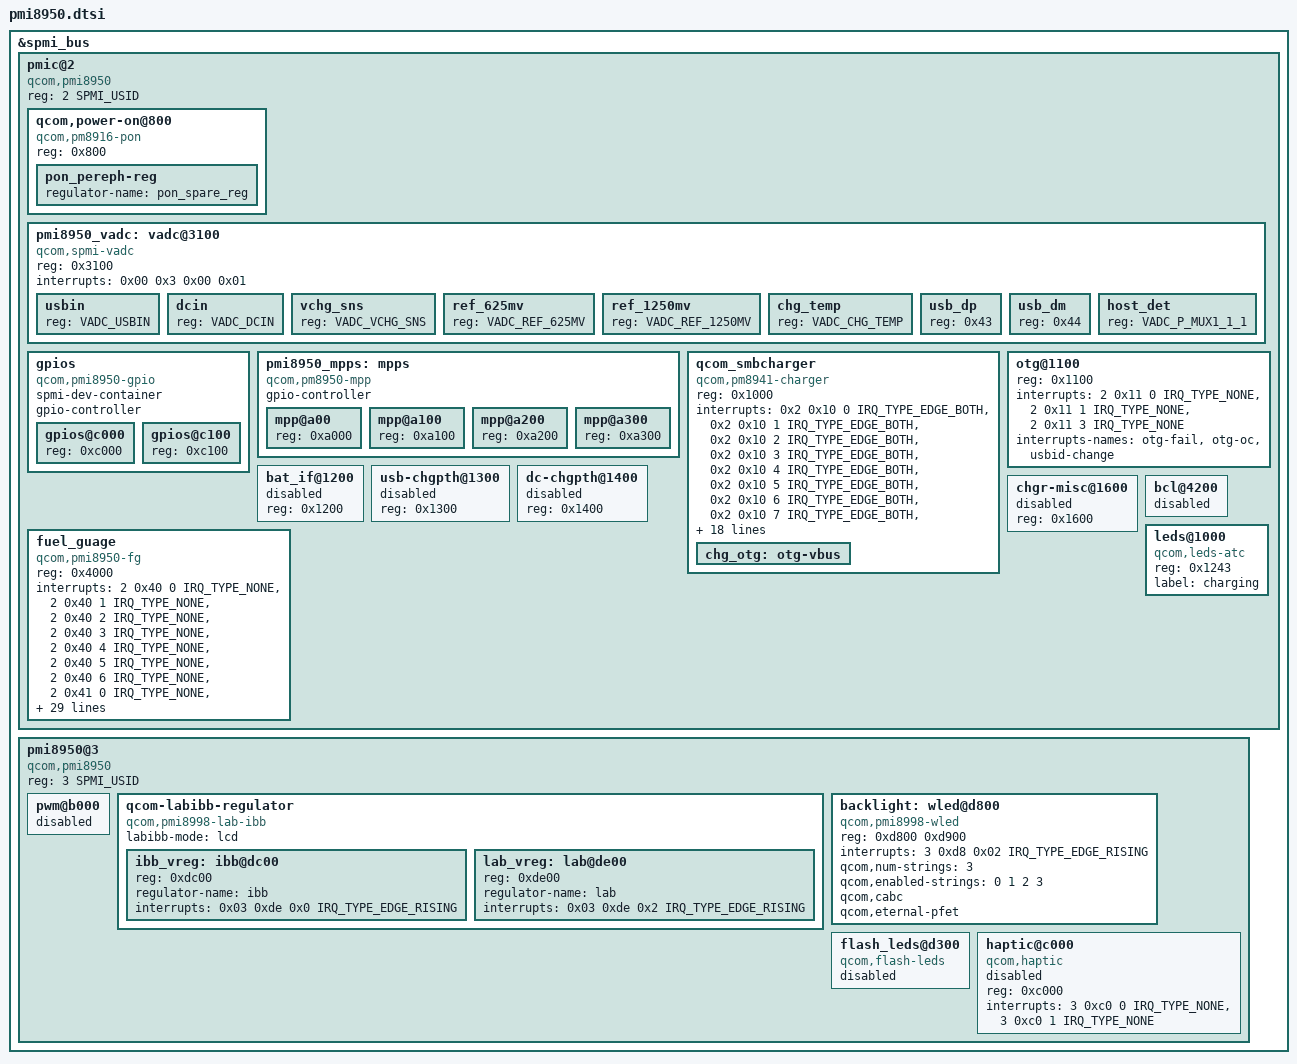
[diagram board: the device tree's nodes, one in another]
// SPDX-License-Identifier: GPL-2.0-only
/* Copyright (c) 2020, The Linux Foundation. All rights reserved.
 */
#include <dt-bindings/iio/qcom,spmi-vadc.h>
#include <dt-bindings/interrupt-controller/irq.h>
#include <dt-bindings/input/linux-event-codes.h>
#include <dt-bindings/spmi/spmi.h>

&spmi_bus {
	pmic@2 {
		compatible = "qcom,pmi8950", "qcom,spmi-pmic";
		reg = <2 SPMI_USID>;
		#address-cells = <1>;
		#size-cells = <0>;

		qcom,power-on@800 {
			compatible = "qcom,pm8916-pon"; //FIXME is this the correct driver
			reg = <0x800>;			//This pmic may be gen2 unlike 8916
			//qcom,secondary-pon-reset;
			//qcom,hard-reset-poweroff-type = <0x04>;
			pon_pereph-reg {
				//TODO:
				regulator-name = "pon_spare_reg";
			};
		};

		pmi8950_vadc: vadc@3100 {
			compatible = "qcom,spmi-vadc";
			reg = <0x3100>;
			interrupts = <0x00 0x3 0x00 0x01>;
			#address-cells = <1>;
			#size-cells = <0>;
			#io-channel-cells = <1>;

			usbin {
				reg = <VADC_USBIN>;
			};

			dcin {
				reg = <VADC_DCIN>;
			};

			vchg_sns {
				reg = <VADC_VCHG_SNS>;
			};

			ref_625mv {
				reg = <VADC_REF_625MV>;
			};

			ref_1250mv {
				reg = <VADC_REF_1250MV>;
			};

			chg_temp {
				reg = <VADC_CHG_TEMP>;
			};

			usb_dp {
				//FIXME: Unsupported?
				reg = <0x43>;
			};

			usb_dm {
				//FIXME: Unsupported?
				reg = <0x44>;
			};

			host_det {
				//FIXME: Unsupported?
				reg = <VADC_P_MUX1_1_1>;
			};
		};

		gpios {
			spmi-dev-container;
			compatible = "qcom,pmi8950-gpio";
			gpio-controller;
			#gpio-cells = <2>;
			#address-cells = <1>;
			#size-cells = <0>;

			gpios@c000 {
				reg = <0xc000>;
				status = "okay";
			};

			gpios@c100 {
				reg = <0xc100>;
				status = "okay";
			};
		};

		pmi8950_mpps: mpps {
			compatible = "qcom,pm8950-mpp";
			gpio-controller;
			#gpio-cells = <2>;
			#address-cells = <1>;
			#size-cells = <0>;

			mpp@a00 {
				reg = <0xa000>;
				status = "okay";
			};

			mpp@a100 {
				reg = <0xa100>;
				status = "okay";
			};

			mpp@a200 {
				reg = <0xa200>;
				status = "okay";
			};

			mpp@a300 {
				reg = <0xa300>;
				status = "okay";
			};
		};

		qcom_smbcharger {
			compatible = "qcom,pm8941-charger";
			reg = <0x1000>;
			status = "okay";

			interrupts = <0x2 0x10 0 IRQ_TYPE_EDGE_BOTH>,
				     <0x2 0x10 1 IRQ_TYPE_EDGE_BOTH>,
				     <0x2 0x10 2 IRQ_TYPE_EDGE_BOTH>,
				     <0x2 0x10 3 IRQ_TYPE_EDGE_BOTH>,
				     <0x2 0x10 4 IRQ_TYPE_EDGE_BOTH>,
				     <0x2 0x10 5 IRQ_TYPE_EDGE_BOTH>,
				     <0x2 0x10 6 IRQ_TYPE_EDGE_BOTH>,
				     <0x2 0x10 7 IRQ_TYPE_EDGE_BOTH>,
				     <0x2 0x12 0 IRQ_TYPE_EDGE_BOTH>,
				     <0x2 0x12 1 IRQ_TYPE_EDGE_BOTH>,
				     <0x2 0x12 2 IRQ_TYPE_EDGE_BOTH>,
				     <0x2 0x12 3 IRQ_TYPE_EDGE_BOTH>,
				     <0x2 0x12 4 IRQ_TYPE_EDGE_BOTH>,
				     <0x2 0x12 5 IRQ_TYPE_EDGE_BOTH>,
				     <0x2 0x12 6 IRQ_TYPE_EDGE_BOTH>,
				     <0x2 0x12 7 IRQ_TYPE_EDGE_BOTH>,
				     <0x2 0x13 0 IRQ_TYPE_EDGE_BOTH>,
				     <0x2 0x13 1 IRQ_TYPE_EDGE_BOTH>,
				     <0x2 0x13 2 IRQ_TYPE_EDGE_BOTH>,
				     <0x2 0x13 5 IRQ_TYPE_EDGE_BOTH>,
				     <0x2 0x16 0 IRQ_TYPE_EDGE_BOTH>,
				     <0x2 0x16 1 IRQ_TYPE_EDGE_BOTH>,
				     <0x2 0x16 2 IRQ_TYPE_EDGE_BOTH>,
				     <0x2 0x16 3 IRQ_TYPE_EDGE_BOTH>,
				     <0x2 0x16 4 IRQ_TYPE_EDGE_BOTH>,
				     <0x2 0x16 5 IRQ_TYPE_EDGE_BOTH>;
			interrupt-names = "chg-error",
					  "chg-inhibit",
					  "chg-prechg-sft",
					  "chg-complete-chg-sft",
					  "chg-p2f-thr",
					  "chg-rechg-thr",
					  "chg-taper-thr",
					  "chg-tcc-thr",
					  "batt-hot",
					  "batt-warm",
					  "batt-cold",
					  "batt-cool",
					  "batt-ov",
					  "batt-low",
					  "batt-missing",
					  "batt-term-missing",
					  "usbin-uv",
					  "usbin-ov",
					  "usbin-src-det",
					  "aicl-done",
					  "power-ok",
					  "temp-shutdown",
					  "wdog-timeout",
					  "flash-fail",
					  "otst2",
					  "otst3";

			chg_otg: otg-vbus { };
		};

		otg@1100 {
			reg = <0x1100>;
			interrupts = <2 0x11 0 IRQ_TYPE_NONE>,
				<2 0x11 1 IRQ_TYPE_NONE>,
				<2 0x11 3 IRQ_TYPE_NONE>;
			interrupts-names = "otg-fail", "otg-oc", "usbid-change";
		};

		bat_if@1200 {
			reg = <0x1200>;
			status = "disabled";
		};

		usb-chgpth@1300 {
			reg = <0x1300>;
			status = "disabled";
		};

		dc-chgpth@1400 {
			reg = <0x1400>;
			status = "disabled";
		};

		chgr-misc@1600 {
			reg = <0x1600>;
			status = "disabled";
		};

		fuel_guage {
			#address-cells = <1>;
			#size-cells = <0>;
			compatible = "qcom,pmi8950-fg";
			reg = <0x4000>;
			interrupts = <2 0x40 0 IRQ_TYPE_NONE>,
				<2 0x40 1 IRQ_TYPE_NONE>,
				<2 0x40 2 IRQ_TYPE_NONE>,
				<2 0x40 3 IRQ_TYPE_NONE>,
				<2 0x40 4 IRQ_TYPE_NONE>,
				<2 0x40 5 IRQ_TYPE_NONE>,
				<2 0x40 6 IRQ_TYPE_NONE>,
				<2 0x41 0 IRQ_TYPE_NONE>,
				<2 0x41 1 IRQ_TYPE_NONE>,
				<2 0x41 2 IRQ_TYPE_NONE>,
				<2 0x41 3 IRQ_TYPE_NONE>,
				<2 0x41 4 IRQ_TYPE_NONE>,
				<2 0x41 5 IRQ_TYPE_NONE>,
				<2 0x41 6 IRQ_TYPE_NONE>,
				<2 0x41 7 IRQ_TYPE_NONE>,
				<2 0x44 0 IRQ_TYPE_NONE>,
				<2 0x44 2 IRQ_TYPE_NONE>;
			interrupt-names = "high-soc",
					"low-soc",
					"full-soc",
					"empty-soc",
					"delta-soc",
					"first-est-done",
					"update-soc",
					"soft-cold",
					"soft-hot",
					"vbatt-low",
					"batt-ided",
					"batt-id-req",
					"batt-unknown",
					"batt-missing",
					"batt-match",
					"mem-avail",
					"data-rcvry-sug";
			qcom,cycle-counter-en;
			qcom,capacity-learning-on;
			qcom,batt-warm-temp = <250>;
			qcom,batt-cool-temp = <0>;
			qcom,batt-hot-temp= <600>;
			qcom,batt-cold-temp = <0xffffff38>;

			qcom,recharge-thr = <99>;
			qcom,delta-soc-thr = <1>;
			qcom,cutoff-volt-mv = <3200>;
			qcom,empty-volt-mv = <3000>;
			qcom,fg-vbat-estimate-diff-mv = <1000>;
			qcom,bcl-lm-thr-ma = <126>;
			qcom,bcl-mh-thr-ma = <400>;
			qcom,term-current-ma = <150>;
			qcom,chg-term-current-ma = <100>;
			qcom,fg-cc-cv-thr-mv = <4390>;

			qcom,cl-vbat-est-thr-uv = <300000>;

			qcom,fg-max-soc = <100>;
			qcom,fg-min-soc = <0>;
			qcom,fg-reset-on-lockup;
		};

		bcl@4200 {
			status = "disabled";
		};

		leds@1000 {
			reg = <0x1243>;
			compatible = "qcom,leds-atc";
			label = "charging";
		};
	};

	pmi8950@3 {
		compatible = "qcom,pmi8950", "qcom,spmi-pmic";
		reg = <3 SPMI_USID>;
		#address-cells = <1>;
		#size-cells = <0>;

		pwm@b000 {
			status = "disabled";
		};

		qcom-labibb-regulator {
			compatible = "qcom,pmi8998-lab-ibb";
			labibb-mode = "lcd";
			#address-cells = <1>;
			#size-cells = <0>;

			ibb_vreg: ibb@dc00 {
				reg = <0xdc00>;
				regulator-name = "ibb";
				interrupts = <0x03 0xde 0x0 IRQ_TYPE_EDGE_RISING>;
				interrupt-names = "ibb-sc-err";
			};

			lab_vreg: lab@de00 {
				reg = <0xde00>;
				regulator-name = "lab";
				interrupts = <0x03 0xde 0x2 IRQ_TYPE_EDGE_RISING>;
				interrupt-names = "lab-sc-err";
			};
		};

		backlight: wled@d800 {
			#address-cells = <1>;
			#size-cells = <0>;
			status = "okay"; // FIXME Is this wled stuff even needed?
			compatible = "qcom,pmi8998-wled";
			reg = <0xd800 0xd900>;

			interrupts = <3 0xd8 0x02 IRQ_TYPE_EDGE_RISING>;
			interrupt-names = "short";

			qcom,num-strings = <3>;
			qcom,enabled-strings = <0 1 2 3>;
			/*The fourth string doesn't exist
			Its put there because otherwise the
			driver gets all 0s in its array*/
			qcom,cabc;
			qcom,eternal-pfet;
		};

		flash_leds@d300 {
			compatible = "qcom,flash-leds";
			status = "disabled";
		};

		haptic@c000 {
			compatible = "qcom,haptic";
			status = "disabled";
			reg = <0xc000>;
			interrupts = <3 0xc0 0 IRQ_TYPE_NONE>,
				<3 0xc0 1 IRQ_TYPE_NONE>;
			interrupt-names = "sc-irq", "play-irq";
		};
	};
};
